# nrf54lm20a_enga_application register map
Vendor: Nordic Semiconductor; Series: nrf54l; File version: 1
CPU: CM33 r0p4, little endian, MPU, FPU, 3 interrupt priority bits, 270 interrupts, 4 SAU regions
Registers are 32-bit, read-write, reset 0x0 unless marked. A register's access mark holds for its fields unless they carry their own. Offsets are from the block's base; [hi:lo] are bit positions; lines under a group give offsets from that group; {n}, {i} and the like mark numbered series.

## GLOBAL_AXONS_NS (part 2 of 2) — Axon wrapper 0
Base 0x40056000
Same registers: GLOBAL_AXONS_S 0x50056000
0x700 AXONDSP group — Unspecified
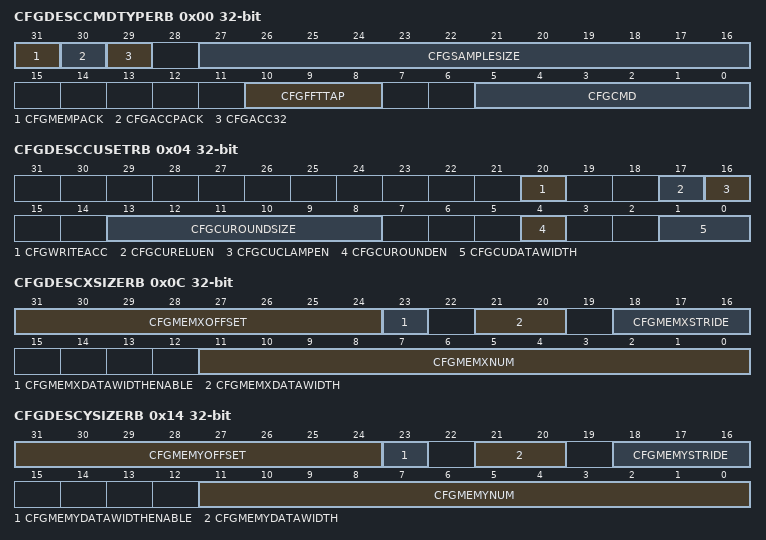
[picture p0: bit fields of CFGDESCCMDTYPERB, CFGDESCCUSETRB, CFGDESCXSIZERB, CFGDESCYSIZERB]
  0x00 CFGDESCCMDTYPERB ro — Read Back for desc[0]. General configuration register for 1000_AXON, desc[0] is manily to set the command type
    [31] CFGMEMPACK — When 1, Samples are packed in system memory according to data width cfg_cu_data_width. When 0, each system memory will contain only one sample.
    [30] CFGACCPACK — When 1, and cfg_write_acc is 1 the accumulator packed in system memory according to data width cfg_cu_data_width and cfg_acc_32. When 0, and cfg_write_acc is 1 the 64bit accumulator is written into system memory.
    [29] CFGACC32 — When 1, and cfg_write_acc and cfg_acc_pack are 1 the 32 bit accumulator is written into system memory. When 0, and cfg_write_acc and cfg_acc_pack are 1 the width of the accumulator written into system memory is determined by cfg_cu_data_width.
    [27:16] CFGSAMPLESIZE — 12 bits, sample size is up to 2048 (12'b100_0000_0000).
    [10:8] CFGFFTTAP — Data TAP size, 512=3'b001,256=3'b010,128=3'b011,64=3'b100,32=3'b101.
    [5:0] CFGCMD — currently it is 5bits [4:0], specify a required operation to be executed. In the notation used below, capital letters (O,X,Y) represent vectors while small letters (o,a,b) represent scalars. When the output is a vector (O) it is written to memory, when the output is scallar (o) is is available in the accumulator status register (which can optionally be written to memory by setting cfg_write_acc in descriptor.)
      0=OPNOP (Unspecified); 1=OPFFT (Unspecified); 2=OPMAR (Unspecified); 3=OPFIR (Unspecified); 4=OPFIRX (Unspecified); 5=OPNORM (Unspecified); 6=OPAXPBY (Unspecified); 8=OPACC (Unspecified); 9=OPXPY (Unspecified); 10=OPXMY (Unspecified); 11=OPAXPB (Unspecified); 12=OPACORR (Unspecified); 13=OPXSPYS (Unspecified); 14=OPXSMYS (Unspecified); 15=OPSQRT (Unspecified); 16=OPLOG (Unspecified); 17=OPEXP (Unspecified); 18=OPXTY (Unspecified); 19=OPXS (Unspecified); 20=OPPREFETCH (Unspecified); 22=OPMARX (Unspecified)
  0x04 CFGDESCCUSETRB ro — Read Back Configuration register for the compute_unit in 1000_AXON
    [20] CFGWRITEACC — Write value of 64bit accumulator into memory indicated by cfg_mem_q_addr. This should be used with coammnds that output the accumulator (ie ACC, MAR, MAR_S, L2NORM)
    [17] CFGCURELUEN — Relu function enable at the output of compute unit. The relu operation zeros out negative numbers. To perform only RELU, use the aX+b with a=1 and b=0
    [16] CFGCUCLAMPEN — Clamping enable. Enabling clamping will saturate outputs and accumulator at their maximum postivie incase of overflow or minimum negative values incase of underflow. The default size for the Accumulator is 64 bits and for outputs is 24 bits. When packing (cfg_mem_pack) is enabled, the size of the output is specified by cfg_cu_data_width. When the accumulator is packed (cfg_acc_pack) and written into memory (cfg_write_acc) the accumulator size is determined by cfg_acc_32 and cfg_cu_data_width.
    [13:8] CFGCUROUNDSIZE — Rounding size. Rounding operation devides output by 2^cfg_cu_round_size. Then rounds up if remainder is more than 0.5 or remainder is exactly 0.5 and quotient is odd. Maximum supported cfg_cu_round_size is 32.
    [4] CFGCUROUNDEN — Rounding enable.
    [1:0] CFGCUDATAWIDTH — real width of data, 08_bit=2'b00,16_bit=2'b01,24_bit=2'b10,12_bit=2'b11.
  0x08 CFGDESCXADDRRB ro — Read Back for X-block configuration register.
    [31:0] CFGDESCXADDR — register address for X-block in SysMem. This address needs to be 16 byte algined when 8 bit packing is used, 8 byte aligned when 12/16 but packing issued and 4 byte aligned otherwise. Recommend to by 16 byte aligned to satisfy all modes.
  0x0C CFGDESCXSIZERB ro — X-block configuration register 2.
    [31:24] CFGMEMXOFFSET — Offset value
    [23] CFGMEMXDATAWIDTHENABLE — Enable use of X block specific data width. Allowed only for MAR operation.
    [21:20] CFGMEMXDATAWIDTH — Data width for X block, when cfg_mem_x_data_width_enable is 1. Otherwise cfg_cu_data_width is used.
    [18:16] CFGMEMXSTRIDE — Stride value, currently it is 2 bits.
    [11:0] CFGMEMXNUM — Effective number of samples in X-block, maximum 2048 12bits. Must by multiple of 4 for (FIR, FIR.X, L2NOM, ACC, MAR,MAR.X. Must be 1024 for ACORR. Must be multiple of 2 for other operations.
  0x10 CFGDESCYADDRRB ro — Y-block configuration register 1.
    [31:0] CFGMEMYADDR — First register address for Y-block in SysMem. This address needs to be 16 byte algined when 8 bit packing is used, 8 byte aligned when 12/16 but packing issued and 4 byte aligned otherwise. Recommend to by 16 byte aligned to satisfy all modes.
  0x14 CFGDESCYSIZERB ro — Y-block configuration register 2.
    [31:24] CFGMEMYOFFSET — Offset value
    [23] CFGMEMYDATAWIDTHENABLE — Enable use of Y block specific data width. Allowed only for MAR operation.
    [21:20] CFGMEMYDATAWIDTH — Data width for Y block, when cfg_mem_y_data_width_enable is 1. Otherwise cfg_cu_data_width is used.
    [18:16] CFGMEMYSTRIDE — Stride value, currently it is 2 bits.
    [11:0] CFGMEMYNUM — Effective number of samples in Y-block, maximum 2048 12bits. Must by multiple of 4 for (FIR, FIR.X, L2NOM, ACC, MAR,MAR.X. Must be 512 for ACORR. Must be multiple of 2 for other operations.
  0x18 CFGDESCAADDRRB ro — A-block configuration register 1.
    [31:0] CFGAADDRRB — First register address for A-block in SysMem. This should also be programmed to the delay value during Auto-Correlation comand (must be even value of delay).
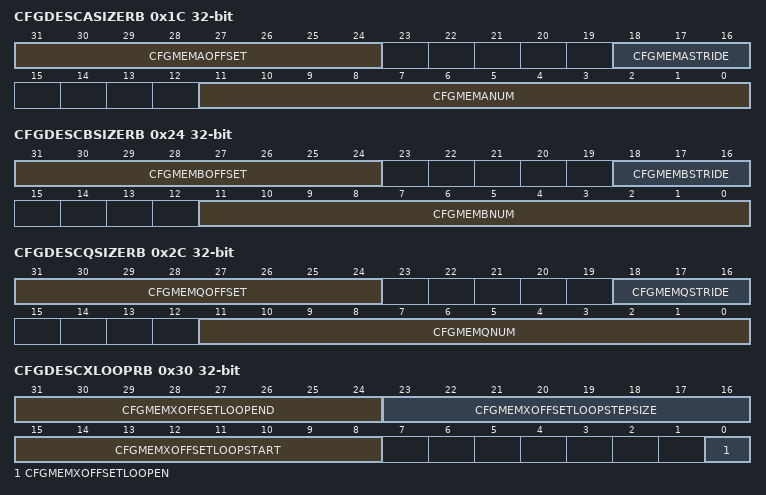
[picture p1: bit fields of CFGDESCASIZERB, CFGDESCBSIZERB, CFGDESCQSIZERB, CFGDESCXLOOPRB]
  0x1C CFGDESCASIZERB ro — A-block configuration register 2.
    [31:24] CFGMEMAOFFSET — Offset value
    [18:16] CFGMEMASTRIDE — Stride value, currently it is 2 bits.
    [11:0] CFGMEMANUM — Effective number of samples in A-block, maximum 2048 12bits. This is a vector only for PREFETCH command. For all other command is a scalar (ie single value). Must be multiple of 2 for Auto-correlation command
  0x20 CFGDESCBADDRRB ro — B-block configuration register 1.
    [31:0] CFGDESCBADDR — First register address for B-block in SysMem.
  0x24 CFGDESCBSIZERB ro — B-block configuration register 2.
    [31:24] CFGMEMBOFFSET — Offset value
    [18:16] CFGMEMBSTRIDE — Stride value, currently it is 2 bits.
    [11:0] CFGMEMBNUM — Effective number of samples in B-block, maximum 2048 12bits.
  0x28 CFGDESCQADDRRB ro — Q-block configuration register 1.
    [31:0] CFGMEMQADDR — First register address for Q-block in SysMem. This address needs to be 16 byte algined when 8 bit packing is used, 8 byte aligned when 12/16 but packing issued and 4 byte aligned otherwise. Recommend to by 16 byte aligned to satisfy all modes. When packing auumulator in memory (cfg_write_acc and cfg_acc_pack are 1), the address must be written in sequence (least signifcant two bits 0,1,2,3 for 8 bit packing and 0,2 for 12/16 bit packing) to trigger writing the packed accumulator into memory.
  0x2C CFGDESCQSIZERB ro — Q-block configuration register 2.
    [31:24] CFGMEMQOFFSET — Offset value
    [18:16] CFGMEMQSTRIDE — Stride value, currently it is 2 bits.
    [11:0] CFGMEMQNUM — Effective number of samples in Q-block, maximum 2048 12bits.
  0x30 CFGDESCXLOOPRB ro — X-block offset loop configuration register.
    [31:24] CFGMEMXOFFSETLOOPEND — Offset loop end
    [23:16] CFGMEMXOFFSETLOOPSTEPSIZE — Offset loop step size
    [15:8] CFGMEMXOFFSETLOOPSTART — Offset loop start
    [0] CFGMEMXOFFSETLOOPEN — Offset loop enable
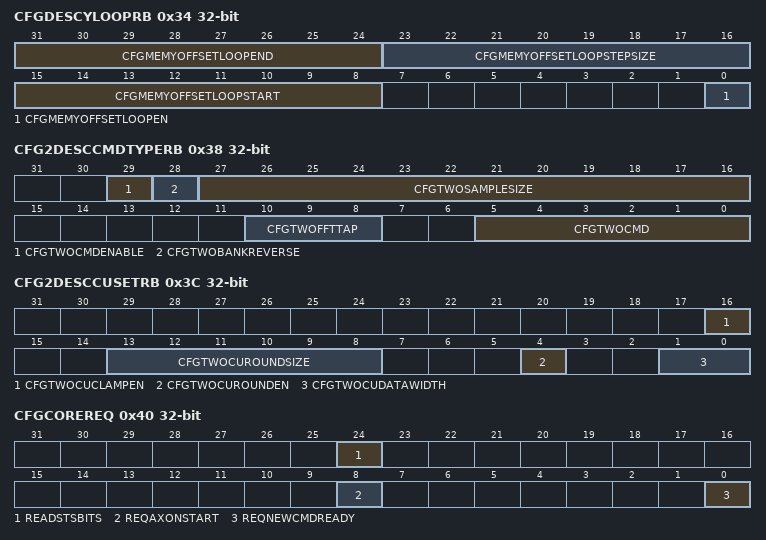
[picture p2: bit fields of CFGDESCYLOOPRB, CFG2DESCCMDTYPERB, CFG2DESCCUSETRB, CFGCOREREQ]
  0x34 CFGDESCYLOOPRB ro — Y-block offset loop configuration register.
    [31:24] CFGMEMYOFFSETLOOPEND — Offset loop end
    [23:16] CFGMEMYOFFSETLOOPSTEPSIZE — Offset loop step size
    [15:8] CFGMEMYOFFSETLOOPSTART — Offset loop start
    [0] CFGMEMYOFFSETLOOPEN — Offset loop enable
  0x38 CFG2DESCCMDTYPERB ro — Read Back for desc[0]. General configuration register for 1000_AXON, desc[0] is manily to set the command type
    [29] CFGTWOCMDENABLE — Enable second command
    [28] CFGTWOBANKREVERSE — Reverse TCM Bank.
    [27:16] CFGTWOSAMPLESIZE — 12 bits, sample size is up to 2048 (12'b100_0000_0000).
    [10:8] CFGTWOFFTTAP — Data TAP size, 512=3'b001,256=3'b010,128=3'b011,64=3'b100,32=3'b101.
    [5:0] CFGTWOCMD — Specifies second command to execute. Encoding is same as cfg_cmd.
  0x3C CFG2DESCCUSETRB ro — Read Back Configuration register for the compute_unit in 1000_AXON
    [16] CFGTWOCUCLAMPEN — Clamping enable.
    [13:8] CFGTWOCUROUNDSIZE — Second Command Rounding size.
    [4] CFGTWOCUROUNDEN — Second Command Rounding enable.
    [1:0] CFGTWOCUDATAWIDTH — Second Command real width of data, 08_bit=2'b00,16_bit=2'b01,24_bit=2'b10,12_bit=2'b11.
  0x40 CFGCOREREQ — core request register
    [24] READSTSBITS — Sample all the status bits which present at the input of Sync_sts cell.
    [8] REQAXONSTART — Start Processing the queued descriptors
    [0] REQNEWCMDREADY — Ready to execute a new command.
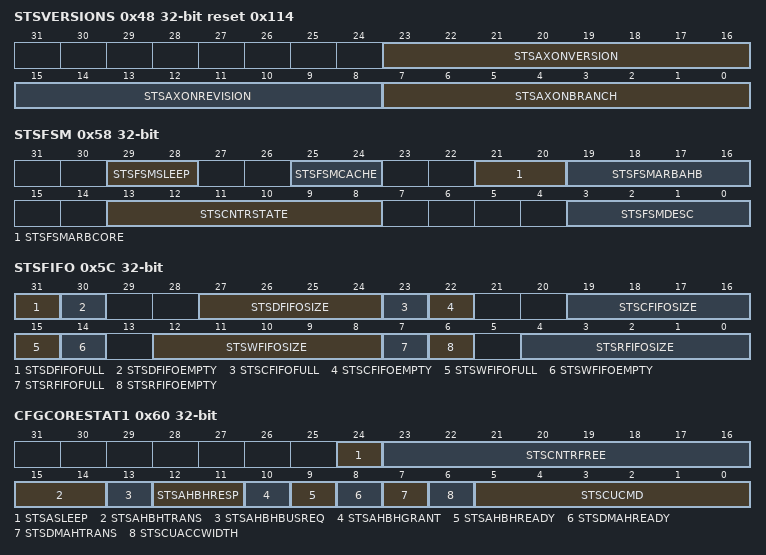
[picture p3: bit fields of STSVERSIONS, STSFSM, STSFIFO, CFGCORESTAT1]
  0x48 STSVERSIONS ro reset 0x114 — AXON Version ID
    [23:16] STSAXONVERSION — AXON Version number.
    [15:8] STSAXONREVISION — AXON revision number
    [7:0] STSAXONBRANCH — AXON branch number
  0x50 STSAHBADDRESS ro — AXON AHB Master last access address
    [31:0] STSAHBHADDR — The address of the last access preformed by AHB master. Must trigger read_sts_bits to update this field.
  0x54 STSDMAADDRESS ro — AXON DMA last access address
    [31:0] STSDMAHADDR — The address of the last access preformedby DMA
  0x58 STSFSM ro — Finite State Machines status register
    [29:28] STSFSMSLEEP — State of sleep statemachine
      0=STATEACTIVE (Unspecified); 1=STATEINACTIVE (Unspecified); 2=STATESLEEP (Unspecified); 3=STATEWAKEUP (Unspecified)
    [25:24] STSFSMCACHE — State of cache statemachine
      0=STATEIDLE (Unspecified); 1=STATEREQ (Unspecified); 2=STATEWRITE (Unspecified); 3=STATEREAD (Unspecified)
    [21:20] STSFSMARBCORE — State of bus arbitor core interface statemachine
      0=STATEIDLE (Unspecified); 1=STATEWRITE (Unspecified); 2=STATEREAD (Unspecified); 3=STATEERR (Unspecified)
    [19:16] STSFSMARBAHB — State of bus arbitor AHB interface satemachine. Must trigger read_sts_bits to update this field.
      0=STATEIDLE (Unspecified); 1=STATEREQ (Unspecified); 2=STATEWRITE (Unspecified); 3=STATEREAD (Unspecified); 4=STATESWRITE (Unspecified); 5=STATESWRITEREQ (Unspecified); 6=STATESREAD (Unspecified); 7=STATESREADREQ (Unspecified); 8=STATEERR (Unspecified); {v}=STATEDUMMY{v-9} (Unspecified) (v=9..15)
    [13:8] STSCNTRSTATE — currently it is 5bits [11:7], Actual state machine in CNTR, used for debug.
      0=CNTRRESET (Unspecified); 1=CNTRWAITCMD (Unspecified); 2=CNTRDMAINITB (Unspecified); 3=CNTRCMDDEC (Unspecified); 4=CNTRDMAINITY (Unspecified); 5=CNTRDMAWAITA (Unspecified); 6=CNTRDMAWAITB (Unspecified); 7=CNTRDMAINITA (Unspecified); 8=CNTRDMAWAITQ (Unspecified); 9=CNTRDMAINITQ (Unspecified); 10=CNTREXECINIT (Unspecified); 11=CNTREXEC (Unspecified); 12=CNTRDMAWAITY (Unspecified); 13=CNTRDMAINITX (Unspecified); 14=CNTREXECPREP (Unspecified); 15=CNTRDMAWAITX (Unspecified); 24=CNTRJOBDONE (Unspecified); 25=CNTRERROR (Unspecified)
    [3:0] STSFSMDESC — State of descriptor statemachine
      0=STATEIDLE (Unspecified); 1=STATEREADFIFO (Unspecified); 2=STATEREQ (Unspecified); 3=STATEWAITDESC (Unspecified); 4=STATESTARTCORE (Unspecified); 5=STATEWAITCORE (Unspecified); 6=STATECOREDONE (Unspecified); 7=STATEACCREQ (Unspecified); 8=STATEACCW0 (Unspecified); 9=STATEACCW1 (Unspecified); 10=STATEACCFLUSH (Unspecified); 11=STATEFINISH (Unspecified); 12=STATEERR (Unspecified); 13=STATEACCCREQ (Unspecified); 14=STATEACCCW (Unspecified); 15=STATEACCCFILL (Unspecified)
  0x5C STSFIFO ro — FIFO Level status register
    [31] STSDFIFOFULL — Descriptor Fifo Full indicator
    [30] STSDFIFOEMPTY — Descriptor Fifo Empty indicator
    [27:24] STSDFIFOSIZE — Number of entries used in Descriptor Fifo
    [23] STSCFIFOFULL — Control Fifo Full indicator
    [22] STSCFIFOEMPTY — Control Fifo Empty indicator. Must trigger read_sts_bits to update this field.
    [19:16] STSCFIFOSIZE — Number of entries used in Control Fifo
    [15] STSWFIFOFULL — Write data Fifo Full indicator
    [14] STSWFIFOEMPTY — Write data Fifo Empty indicator. Must trigger read_sts_bits to update this field.
    [12:8] STSWFIFOSIZE — Number of entries used in Write data Fifo
    [7] STSRFIFOFULL — Read data Fifo Full indicator. Must trigger read_sts_bits to update this field.
    [6] STSRFIFOEMPTY — Read data Fifo Empty indicator
    [4:0] STSRFIFOSIZE — Number of entries used in Read data Fifo
  0x60 CFGCORESTAT1 ro — AXON status register 1
    [24] STSASLEEP — When logic 1, indicatesAXON is in sleep state. Any register write will wakeup AXON.
    [23:16] STSCNTRFREE — The value of free entried in the read fifo.
    [15:14] STSAHBHTRANS — The value of AHB master htrans output. Must trigger read_sts_bits to update this field.
    [13] STSAHBHBUSREQ — The value of AHB master hbusreq output. Must trigger read_sts_bits to update this field.
    [12:11] STSAHBHRESP — The value of AHB master hresp input. Must trigger read_sts_bits to update this field.
    [10] STSAHBHGRANT — The value of AHB master hgrant input. Must trigger read_sts_bits to update this field.
    [9] STSAHBHREADY — The value of AHB master hready input. Must trigger read_sts_bits to update this field.
    [8] STSDMAHREADY — The value of internal dma hready
    [7] STSDMAHTRANS — The value of internal dma htrans[1]
    [6] STSCUACCWIDTH — The width of ACC output 24bit=1'b0,32bit=1'b1.
    [5:0] STSCUCMD — currently it is 4bits [3:0], running operation in CU, used for debug.
  0x64 CFGCORESTAT2 ro — AXON status register 2
    [31:0] STSACCRESULT — ACC output. This is accumulator[31:0]
  0x68 CFGCORESTAT3 ro — AXON status register 2 extended to 64.
    [31:0] STSACCRESULTE — ACC output. This is accumulator[63:32]
  0x6C CFGCOREDESCSTARTADDR — This register contains pointer to AXON descriptor, the value will be stored inside FIFO
    [31:0] DESCSTARTADDR — start address of the descriptors in system memory.
  0x70 CFGCORECURRDESCSTARTADDRRB ro — current descriptor address readback
    [31:0] DESCADDRRB — readback the current descriptor address
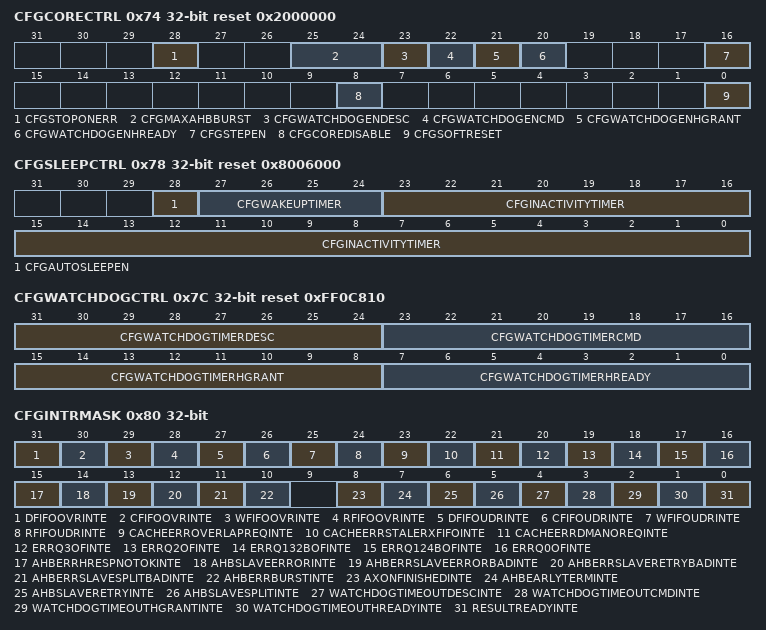
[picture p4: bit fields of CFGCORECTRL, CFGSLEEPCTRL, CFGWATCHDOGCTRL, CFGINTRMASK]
  0x74 CFGCORECTRL reset 0x2000000 — Configuration register for 0010_AXON
    [28] CFGSTOPONERR — set 1, AXON will stop when an error is detected for FW to perform a sw reset using cfg_soft_reset. When 0, AXON statemachine will keep going when an error is detected.
    [25:24] CFGMAXAHBBURST — Specifies the maximum allowed burst size on the master AHB port.
      0=NONE (Unspecified); 1=FOURBEATS (Unspecified); 2=EIGHTBEATS (Unspecified); 3=SIXTEENBEATS (Unspecified)
    [23] CFGWATCHDOGENDESC — set 1 to enable watchdog timer for processing all the descriptors. set 0 to disable watchdog timer.
    [22] CFGWATCHDOGENCMD — set 1 to enable watchdog timer for processing each command. set 0 to disable watchdog timer.
    [21] CFGWATCHDOGENHGRANT — set 1 to enable watchdog timer for receiving hgrant on AHB master port. set 0 to disable watchdog timer.
    [20] CFGWATCHDOGENHREADY — set 1 to enable watchdog timer for receiving hready on AHB master port. set 0 to disable watchdog timer.
    [16] CFGSTEPEN — set 1 to enable FW to step each descriptor processed by triggering req_new_cmd_ready. set 0 so no FW involvement is needed per descriptor.
    [8] CFGCOREDISABLE — Active high clock gating. Does not gate off clock to LBI configuration registers to avoid lockup. This can be used to measure AXON leakage power in silicon when clocks are disabled.
      0=CLOCKENABLED (Unspecified); 1=CLOCKDISABLED (Unspecified)
    [0] CFGSOFTRESET — Active high soft reset of the AXON IP. Does not reset configuration registers. Reset is performed asynchronously. Deassertion of reset is synchronoush and only takes a few cycles to propagate through synchrnonizers. Should be used to recover from any error interrupt by performing soft reset, then clearing all interrupts then retrying all descriptor batch.
      0=NORMALOPERATION (Unspecified); 1=RESET (Unspecified)
  0x78 CFGSLEEPCTRL reset 0x8006000 — Configuration register for Sleep Control
    [28] CFGAUTOSLEEPEN — When logic 1, The AXON will sleep if there is no commands to process for the duraction of the time specified by cfg_inactivity_timer. The axon will automatically wakeup if any registers are written. Register reads will leave the axon in sleep. When logic 0, AXON will not go into sleep mode.
    [27:24] CFGWAKEUPTIMER — AXON will wait for the number of progammed cycles after wakeup to allow clock to settle.
    [23:0] CFGINACTIVITYTIMER — The umber of clock cycles of inactivity to wait before going to sleep
  0x7C CFGWATCHDOGCTRL reset 0xFF0C810 — Configuration register for Watchdog Control
    [31:24] CFGWATCHDOGTIMERDESC — AXON will wait the programmed number of clock cyles (x 2^16) for all the descriptos to finish processing, otherwise the watchdog timer will expire and trigger an interrupt.
    [23:16] CFGWATCHDOGTIMERCMD — AXON will wait the programmed number of clock cyles (x 2^8) for a command to finish processing, otherwise the watchdog timer will expire and trigger an interrupt.
    [15:8] CFGWATCHDOGTIMERHGRANT — AXON will wait the programmed number of clock cyles to receive hgrant on AHB master port when requesting the bus, otherwise the watchdog timer will expire and trigger an interrupt.
    [7:0] CFGWATCHDOGTIMERHREADY — AXON will wait the programmed number of clock cyles to receive hready on AHB master port, otherwise the watchdog timer will expire and trigger an interrupt.
  0x80 CFGINTRMASK — Interupt enable register for AXON core
    [all] fields
      0=INTERRUPTDISABLED (Unspecified); 1=INTERRUPTENABLED (Unspecified)
    [31] DFIFOOVRINTE — Enable generating Descriptor Fifo Overun error interupt.
    [30] CFIFOOVRINTE — Enable generating Control Fifo Overun error interupt.
    [29] WFIFOOVRINTE — Enable generating Write data Fifo Overun error interupt.
    [28] RFIFOOVRINTE — Enable generating Read data Fifo Overun error interupt.
    [27] DFIFOUDRINTE — Enable generating Descriptor Fifo Underrun error interupt.
    [26] CFIFOUDRINTE — Enable generating Control Fifo Underrun error interupt.
    [25] WFIFOUDRINTE — Enable generating Write data Fifo Underrun error interupt.
    [24] RFIFOUDRINTE — Enable generating Read data Fifo Underrun error interupt.
    [23] CACHEERROVERLAPREQINTE — Enable generating corresponding cache error interupt.
    [22] CACHEERRSTALERXFIFOINTE — Enable generating corresponding cache error interupt.
    [21] CACHEERRDMANOREQINTE — Enable generating corresponding cache error interupt.
    [20] ERRQ3OFINTE — Enable generating error Q3 overflow interupt.
    [19] ERRQ2OFINTE — Enable generating error Q2 overflow interupt.
    [18] ERRQ132BOFINTE — Enable generating error 64_bit Accumualtor overflow interupt.
    [17] ERRQ124BOFINTE — Enable generating error 24_bit Q1 output overflow interupt.
    [16] ERRQ0OFINTE — Enable generating error Q0 overflow interupt.
    [15] AHBERRHRESPNOTOKINTE — Enable generating interupt when following AHB behavior occurs. The slave did not follow the AHB protocol and responded with HRESP not being OKAY when expected
    [14] AHBSLAVEERRORINTE — Enable generating interupt when following AHB behavior occurs. The slave is indicating an error has occurred with the access
    [13] AHBERRSLAVEERRORBADINTE — Enable generating interupt when following AHB behavior occurs. The slave did not follow the AHB protocol when giving the HRESP ERROR
    [12] AHBERRSLAVERETRYBADINTE — Enable generating interupt when following AHB behavior occurs. The slave did not follow the AHB protocol when giving the HRESP RETRY
    [11] AHBERRSLAVESPLITBADINTE — Enable generating interupt when following AHB behavior occurs. The slave did not follow the AHB protocol when giving the HRESP SPLIT
    [10] AHBERRBURSTINTE — Enable generating interupt when following AHB behavior occurs. The master didnt provide the complete data for the entire burst.
    [8] AXONFINISHEDINTE — Enable generating interupt when AXON finished processing all queued descriptors
    [7] AHBEARLYTERMINTE — Enable generating interupt when AHB arbitor has terminated a burst early
    [6] AHBSLAVERETRYINTE — Enable generating interupt when AHB slave is telling the master to RETRY
    [5] AHBSLAVESPLITINTE — Enable generating interupt when AHB slave is telling the master to SPLIT
    [4] WATCHDOGTIMEOUTDESCINTE — Enable generating interupt when AXON watchdog timesout for processing all descriptors
    [3] WATCHDOGTIMEOUTCMDINTE — Enable generating interupt when AXON watchdog timesout for processing a command
    [2] WATCHDOGTIMEOUTHGRANTINTE — Enable generating interupt when AXON watchdog timesout for receiving hgrant
    [1] WATCHDOGTIMEOUTHREADYINTE — Enable generating interupt when AXON watchdog timesout for receiving hready
    [0] RESULTREADYINTE — Enable generating interupt when AXON achieves any task and the results are ready to be read.
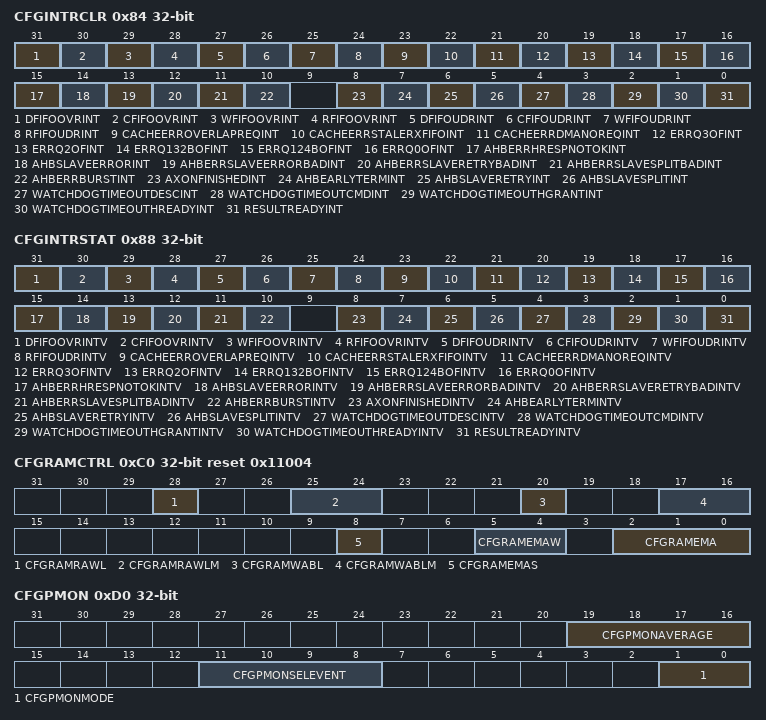
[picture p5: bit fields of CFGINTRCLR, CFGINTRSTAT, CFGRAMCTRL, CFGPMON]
  0x84 CFGINTRCLR — Interupt clear
    [all] fields
      0=NOEVENT (Unspecified); 1=EVENT (Unspecified)
    [31] DFIFOOVRINT — Descriptor Fifo Overrun error Interupt.
    [30] CFIFOOVRINT — Control Fifo Overrun error Interupt.
    [29] WFIFOOVRINT — Write data Fifo Overrun error Interupt.
    [28] RFIFOOVRINT — Read data Fifo Overrun error Interupt.
    [27] DFIFOUDRINT — Descriptor Fifo Underrun error Interupt.
    [26] CFIFOUDRINT — Control Fifo Underrun error Interupt.
    [25] WFIFOUDRINT — Write Data Fifo Underrun error Interupt.
    [24] RFIFOUDRINT — Read data Fifo Underrun error Interupt.
    [23] CACHEERROVERLAPREQINT — Cache overlap request error Interupt.
    [22] CACHEERRSTALERXFIFOINT — Cache Stale data in receive FIFO error Interupt.
    [21] CACHEERRDMANOREQINT — Cache DMA access without active request error Interupt.
    [20] ERRQ3OFINT — Q3 overflow error Interupt. Tied off.
    [19] ERRQ2OFINT — Q2 overflow error Interupt. Tied off
    [18] ERRQ132BOFINT — 64_bit Accumulator overflow error Interupt.
    [17] ERRQ124BOFINT — 24_bit Q1 output overflow error Interupt.
    [16] ERRQ0OFINT — Q0 overflow error Interupt. Tied off
    [15] AHBERRHRESPNOTOKINT — Interupt event occures when the following AHB event occurs. The slave did not follow the AHB protocol and responded with HRESP not being OKAY when expected
    [14] AHBSLAVEERRORINT — Interupt event occures when the following AHB event occurs. The slave is indicating an error has occurred with the access
    [13] AHBERRSLAVEERRORBADINT — Interupt event occures when the following AHB event occurs. The slave did not follow the AHB protocol when giving the HRESP ERROR
    [12] AHBERRSLAVERETRYBADINT — Interupt event occures when the following AHB event occurs. The slave did not follow the AHB protocol when giving the HRESP ERROR
    [11] AHBERRSLAVESPLITBADINT — Interupt event occures when the following AHB event occurs. The slave did not follow the AHB protocol when giving the HRESP SPLIT
    [10] AHBERRBURSTINT — Interupt event occures when the following AHB event occurs. The master didnt provide the complete data for the entire burst
    [8] AXONFINISHEDINT — Interupt event occures when the AXON finishes processing all descriptors. FW needs to check all other error interrupts (result_ready_int is OK) are not not asserted to determine that the descriptor execution was successfull.
    [7] AHBEARLYTERMINT — Interupt event occures when the AHB arbitor has terminated a burst early
    [6] AHBSLAVERETRYINT — Interupt event occures when the AHB slave is telling the master to RETRY
    [5] AHBSLAVESPLITINT — Interupt event occures when the AHB slave is telling the master to SPLIT
    [4] WATCHDOGTIMEOUTDESCINT — Interupt event occures when the all desciptors are not processed within specified timeout limit.
    [3] WATCHDOGTIMEOUTCMDINT — Interupt event occures when a command is not processed within specified timeout limit.
    [2] WATCHDOGTIMEOUTHGRANTINT — Interupt event occures when the AHB master bus is not granted within specified timeout limit.
    [1] WATCHDOGTIMEOUTHREADYINT — Interupt event occures when AHB master bus is not ready within specified timeout limit.
    [0] RESULTREADYINT — Interupt event occures when the AXON task is done processing one descriptor. This is intended mainly for debug purposes.
  0x88 CFGINTRSTAT ro — Interupt status register
    [31] DFIFOOVRINTV — Descriptor Fifo Overrun error Interupt_V.
    [30] CFIFOOVRINTV — Control Fifo Overrun error Interupt_V.
    [29] WFIFOOVRINTV — Write data Fifo Overrun error Interupt_V.
    [28] RFIFOOVRINTV — Read data Fifo Overrun error Interupt_V.
    [27] DFIFOUDRINTV — Descriptor Fifo Underrun error Interupt_V.
    [26] CFIFOUDRINTV — Control Fifo Underrun error Interupt_V.
    [25] WFIFOUDRINTV — Write data Fifo Underrun error Interupt_V.
    [24] RFIFOUDRINTV — Read data Fifo Underrun error Interupt_V.
    [23] CACHEERROVERLAPREQINTV — Cache overlap request error Interupt_V.
    [22] CACHEERRSTALERXFIFOINTV — Cache stale data in recevie FIFO error Interupt_V.
    [21] CACHEERRDMANOREQINTV — Cache DMA access without active request error Interupt_V.
    [20] ERRQ3OFINTV — Q3 overflow error Interupt_V. Tied off to 0
    [19] ERRQ2OFINTV — Q2 overflow error Interupt_V. Tied off to 0
    [18] ERRQ132BOFINTV — 64-bit Accumulator overflow error Interupt_V.
    [17] ERRQ124BOFINTV — 24-bit Q1 output overflow error Interupt_V.
    [16] ERRQ0OFINTV — Q0 overflow error Interupt_V. Tied off to 0
    [15] AHBERRHRESPNOTOKINTV — AHB Error HRESP not OK Interupt_V.
    [14] AHBSLAVEERRORINTV — AHB Slave Error Interupt_V.
    [13] AHBERRSLAVEERRORBADINTV — AHB error slave error bad Interupt_V.
    [12] AHBERRSLAVERETRYBADINTV — AHB error slave retry bad Interupt_V.
    [11] AHBERRSLAVESPLITBADINTV — AHB error slave split bad Interupt_V.
    [10] AHBERRBURSTINTV — AHB error burst Interupt_V.
    [8] AXONFINISHEDINTV — AXON_Finished Interupt_V.
    [7] AHBEARLYTERMINTV — AHB early termination Interupt_V.
    [6] AHBSLAVERETRYINTV — AHB slave retry Interupt_V.
    [5] AHBSLAVESPLITINTV — AHB slave split Interupt_V.
    [4] WATCHDOGTIMEOUTDESCINTV — Descriptor Watchdog timeout Interupt_V.
    [3] WATCHDOGTIMEOUTCMDINTV — Command Watchdog timeout Interupt_V.
    [2] WATCHDOGTIMEOUTHGRANTINTV — AHB master hgrant Watchdog timeout Interupt_V.
    [1] WATCHDOGTIMEOUTHREADYINTV — AHB master hready Watchdog timeout Interupt_V.
    [0] RESULTREADYINTV — Result_ready Interupt_V.
  0xC0 CFGRAMCTRL reset 0x11004 — 22nm TSMC ram control register
    [28] CFGRAMRAWL — Ram setting to enable read margin
    [25:24] CFGRAMRAWLM — Ram setting for read margin
    [20] CFGRAMWABL — Ram setting to enable write margin
    [17:16] CFGRAMWABLM — Ram setting for write margin
    [8] CFGRAMEMAS — RAM setting to enable bitline keepr
    [5:4] CFGRAMEMAW — Ram setting to slow write access
    [2:0] CFGRAMEMA — RAM setting to slow read access
  0xD0 CFGPMON — Performance Monitor Configuration Register
    [19:16] CFGPMONAVERAGE — Amount of averaging in latency measurement mode. Value is 2 ^ cfg_pmon_average. 0 means no averaging. 1 means average two measurements. 2 means average 4 measurements. 3 means average 8 measurments, and so on
    [11:8] CFGPMONSELEVENT — Select which event to count or measure latency
      0=NUMINTERRUPTCYCLES (Unspecified); 1=NUMIDLECYCLES (Unspecified); 2=NUMBUSYCYCLES (Unspecified); 3=NUMFINISHEDBATCHES (Unspecified); 4=NUMDESCRIPTORS (Unspecified); 5=NUMDESCRIPTORFETCHCYCLES (Unspecified); 6=NUMDESCRIPTOREXECUTECYCLES (Unspecified); 7=NUMFLUSHOUTPUTCYCLES (Unspecified); 8=NUMWRITECYCLES (Unspecified); 9=NUMREADCYCLES (Unspecified); 10=NUMWRITEWAITCYCLES (Unspecified); 11=NUMREADWAITCYCLES (Unspecified); 12=NUMFIRSTREADWAITCYCLES (Unspecified); 13=NUMRESTREADWAITCYCLES (Unspecified); 14=NUMBUSCYCLES (Unspecified); 15=NUMBUSWAITCYCLES (Unspecified)
    [1:0] CFGPMONMODE — Performance Monitor Mode of Operation.
      0=DISABLED (Unspecified); 1=FREERUNNING (Unspecified); 2=EVENTCOUNT (Unspecified); 3=EVENTLATENCY (Unspecified)
  0xD4 REQPMON — Core Request Register
    [28] REQPMONTRIG — Update sts_pmon_msb_cnt and sts_pmon_lsb_cnt. Not required in free running mode.
  0xD8 STSPMONMSB ro — Performance Counter Most Significant Word
    [31:0] STSPMONMSBCNT — Perfromance counter bits 63 to 32. Must trigger req_core_pmon_trig to update, except in free running mode
  0xDC STSPMONLSB ro — Performance Counter Least Significant Word
    [31:0] STSPMONLSBCNT — Performance counter bits 31 to 0. Must trigger req_core_pmon_trig to update, except in free running mode
0xC00 PCGCSLAVE group — Unspecified
  {0x0+4j} PENALTY[{j}] (j=0..1) reset 0xFFFFFFFC — Description collection: Penalty level for power/clock pair n. When FULL_PCP_ZERO feature is not supported, PENALTY[0] address overlaps the PENALTY0 address and register description for PENALTY[0] is not valid.
    [1:0] PENALTY — Penalty level
  0x00 PENALTY0 (alternate view of PENALTY[*]) — Penalty level for power/clock pair 0. The register description is valid only when FULL_PCP_ZERO feature is not supported
    [1:0] PENALTY ro — Penalty level
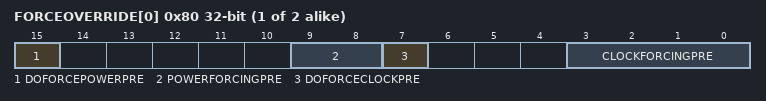
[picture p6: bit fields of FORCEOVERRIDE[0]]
  {0x80+4j} FORCEOVERRIDE[{j}] (j=0..1) — Description collection: Force override of power/clock pair n.
    [15] DOFORCEPOWERPRE, [9:8] POWERFORCINGPRE, [7] DOFORCECLOCKPRE, [3:0] CLOCKFORCINGPRE
